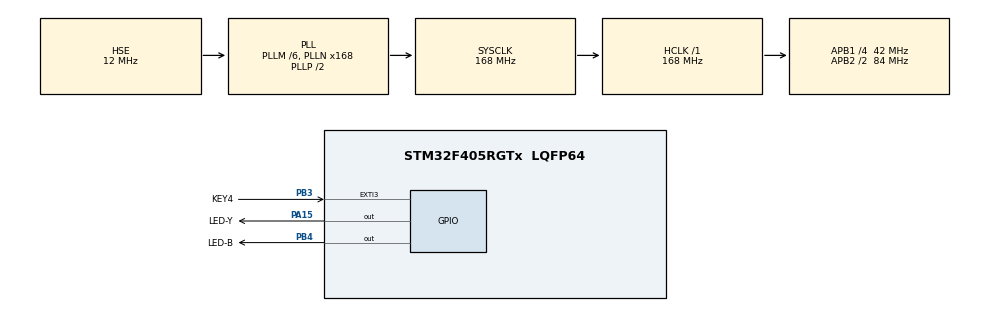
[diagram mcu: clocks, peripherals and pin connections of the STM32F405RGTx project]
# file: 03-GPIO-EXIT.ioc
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Mcu.Family=STM32F4
RCC.PLLSourceVirtual=RCC_PLLSOURCE_HSE
PH0-OSC_IN.Signal=RCC_OSC_IN
RCC.CortexFreq_Value=168000000
NVIC.EXTI3_IRQn=true\:0\:0\:false\:false\:true\:true\:true
PB3.GPIO_ModeDefaultEXTI=GPIO_MODE_IT_RISING
RCC.APB1CLKDivider=RCC_HCLK_DIV4
RCC.SYSCLKSource=RCC_SYSCLKSOURCE_PLLCLK
ProjectManager.StackSize=0x400
PA13.Signal=SYS_JTMS-SWDIO
PA15.GPIO_Label=LED-Y
ProjectManager.TargetToolchain=MDK-ARM V5.27
RCC.HCLKFreq_Value=168000000
RCC.APB2TimFreq_Value=168000000
PB4.GPIO_PuPd=GPIO_PULLDOWN
RCC.LSE_VALUE=32768
RCC.AHBFreq_Value=168000000
PH0-OSC_IN.Mode=HSE-External-Oscillator
RCC.HSE_VALUE=12000000
board=custom
RCC.VCOOutputFreq_Value=336000000
PA15.PinState=GPIO_PIN_SET
PB4.GPIO_Speed=GPIO_SPEED_FREQ_HIGH
RCC.APB2Freq_Value=84000000
PB3.GPIO_PuPd=GPIO_PULLUP
PB4.GPIO_Label=LED-B
PA14.Mode=Serial_Wire
PH1-OSC_OUT.Signal=RCC_OSC_OUT
PA13.Mode=Serial_Wire
Mcu.Name=STM32F405RGTx
PH1-OSC_OUT.Mode=HSE-External-Oscillator
RCC.48MHZClocksFreq_Value=84000000
PB3.Signal=GPXTI3
RCC.SYSCLKFreq_VALUE=168000000
Mcu.Package=LQFP64
PA15.GPIO_Speed=GPIO_SPEED_FREQ_HIGH
PA14.Signal=SYS_JTCK-SWCLK
PA15.Signal=GPIO_Output
ProjectManager.HeapSize=0x200
RCC.HSI_VALUE=16000000
NVIC.PriorityGroup=NVIC_PRIORITYGROUP_4
RCC.APB2CLKDivider=RCC_HCLK_DIV2
RCC.PLLM=6
RCC.PLLN=168
PA15.GPIO_PuPd=GPIO_PULLDOWN
RCC.APB1TimFreq_Value=84000000
RCC.APB1Freq_Value=42000000
PB4.PinState=GPIO_PIN_SET
PB4.Signal=GPIO_Output
PB3.GPIO_Label=KEY4

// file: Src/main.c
/* USER CODE BEGIN Header */
/**
  ******************************************************************************
  * @file           : main.c
  * @brief          : Main program body
  ******************************************************************************
  * @attention
  *
  * <h2><center>&copy; Copyright (c) 2020 STMicroelectronics.
  * All rights reserved.</center></h2>
  *
  * This software component is licensed by ST under BSD 3-Clause license,
  * the "License"; You may not use this file except in compliance with the
  * License. You may obtain a copy of the License at:
  *                        opensource.org/licenses/BSD-3-Clause
  *
  ******************************************************************************
  */
/* USER CODE END Header */

#include "main.h"
#include "gpio.h"

void SystemClock_Config(void);

/* USER CODE BEGIN 0 */
void HAL_GPIO_EXTI_Callback(uint16_t GPIO_Pin)
{
	if((GPIO_Pin == KEY4_Pin) && (HAL_GPIO_ReadPin(KEY4_GPIO_Port,KEY4_Pin)==1))
		HAL_GPIO_TogglePin(LED_B_GPIO_Port,LED_B_Pin);
}
/* USER CODE END 0 */

int main(void)
{

  /* MCU Configuration--------------------------------------------------------*/

  /* Reset of all peripherals, Initializes the Flash interface and the Systick. */
  HAL_Init();

  /* Configure the system clock */
  SystemClock_Config();

  /* Initialize all configured peripherals */
  MX_GPIO_Init();

  /* Infinite loop */
  while (1)
  {

  }
}

void SystemClock_Config(void)
{
  RCC_OscInitTypeDef RCC_OscInitStruct = {0};
  RCC_ClkInitTypeDef RCC_ClkInitStruct = {0};

  /** Configure the main internal regulator output voltage
  */
  __HAL_RCC_PWR_CLK_ENABLE();
  __HAL_PWR_VOLTAGESCALING_CONFIG(PWR_REGULATOR_VOLTAGE_SCALE1);
  /** Initializes the CPU, AHB and APB busses clocks
  */
  RCC_OscInitStruct.OscillatorType = RCC_OSCILLATORTYPE_HSE;
  RCC_OscInitStruct.HSEState = RCC_HSE_ON;
  RCC_OscInitStruct.PLL.PLLState = RCC_PLL_ON;
  RCC_OscInitStruct.PLL.PLLSource = RCC_PLLSOURCE_HSE;
  RCC_OscInitStruct.PLL.PLLM = 6;
  RCC_OscInitStruct.PLL.PLLN = 168;
  RCC_OscInitStruct.PLL.PLLP = RCC_PLLP_DIV2;
  RCC_OscInitStruct.PLL.PLLQ = 4;
  if (HAL_RCC_OscConfig(&RCC_OscInitStruct) != HAL_OK)
  {
    Error_Handler();
  }
  /** Initializes the CPU, AHB and APB busses clocks
  */
  RCC_ClkInitStruct.ClockType = RCC_CLOCKTYPE_HCLK|RCC_CLOCKTYPE_SYSCLK
                              |RCC_CLOCKTYPE_PCLK1|RCC_CLOCKTYPE_PCLK2;
  RCC_ClkInitStruct.SYSCLKSource = RCC_SYSCLKSOURCE_PLLCLK;
  RCC_ClkInitStruct.AHBCLKDivider = RCC_SYSCLK_DIV1;
  RCC_ClkInitStruct.APB1CLKDivider = RCC_HCLK_DIV4;
  RCC_ClkInitStruct.APB2CLKDivider = RCC_HCLK_DIV2;

  if (HAL_RCC_ClockConfig(&RCC_ClkInitStruct, FLASH_LATENCY_5) != HAL_OK)
  {
    Error_Handler();
  }
}

void Error_Handler(void)
{
}

/************************ (C) COPYRIGHT STMicroelectronics *****END OF FILE****/
